AUTOSAR XML (schema 00052)
package /apd/AdaptiveApplicationSwComponentTypes
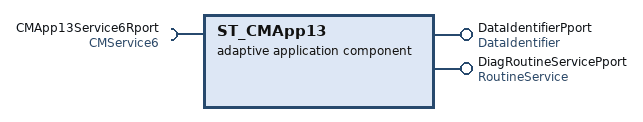
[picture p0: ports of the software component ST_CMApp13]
  adaptive application sw component type ST_CMApp13
    require port CMApp13Service6Rport: required-interface=CMService6
    provide port DataIdentifierPport: provided-interface=DataIdentifier
    provide port DiagRoutineServicePport: provided-interface=RoutineService
package /apd/Executables
  executable ST_CMApp13: category=APPLICATION_LEVEL, minimum-timer-granularity=1000.0
    root sw component prototype ST_CMApp13Root: application-type=ST_CMApp13
